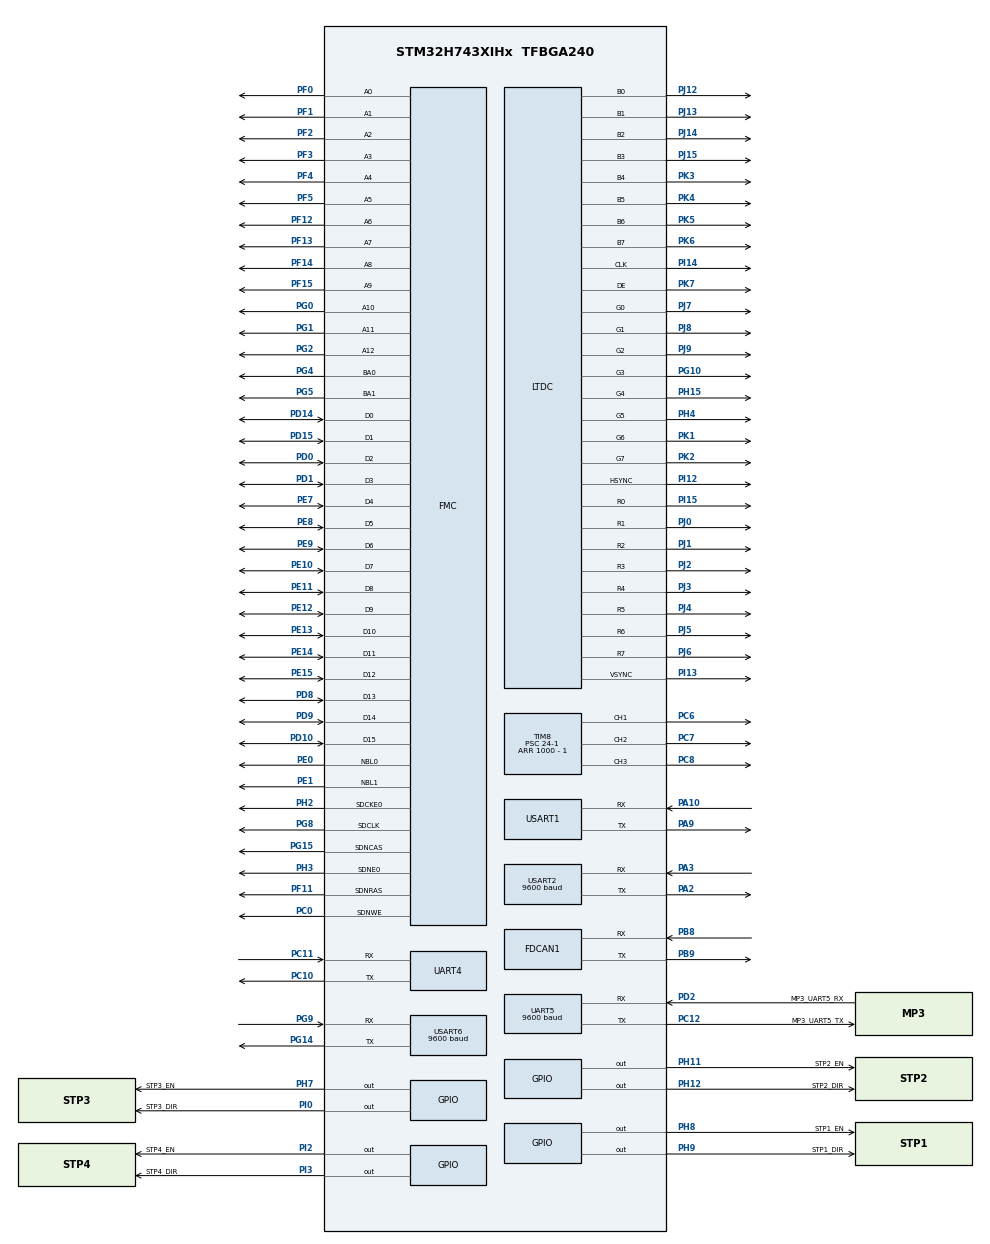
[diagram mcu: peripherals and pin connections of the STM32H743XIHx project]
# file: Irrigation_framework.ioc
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CORTEX_M7.AccessPermission_S-Cortex_Memory_Protection_Unit_Region1_Settings_S=MPU_REGION_FULL_ACCESS
CORTEX_M7.AccessPermission_Spec=MPU_REGION_FULL_ACCESS
CORTEX_M7.BaseAddress_S-Cortex_Memory_Protection_Unit_Region1_Settings_S=0xC0000000
CORTEX_M7.BaseAddress_Spec=0x24000000
CORTEX_M7.CPU_DCache=Enabled
CORTEX_M7.CPU_ICache=Enabled
CORTEX_M7.DisableExec_Spec=MPU_INSTRUCTION_ACCESS_ENABLE
CORTEX_M7.Enable_S-Cortex_Memory_Protection_Unit_Region1_Settings_S=MPU_REGION_ENABLE
CORTEX_M7.Enable_S-Cortex_Memory_Protection_Unit_Region2_Settings_S=__NULL
CORTEX_M7.Enable_S-Cortex_Memory_Protection_Unit_Region3_Settings_S=__NULL
CORTEX_M7.Enable_S-Cortex_Memory_Protection_Unit_Region4_Settings_S=__NULL
CORTEX_M7.Enable_S-Cortex_Memory_Protection_Unit_Region5_Settings_S=__NULL
CORTEX_M7.Enable_S-Cortex_Memory_Protection_Unit_Region6_Settings_S=__NULL
CORTEX_M7.Enable_Spec=MPU_REGION_ENABLE
CORTEX_M7.IsBufferable_S-Cortex_Memory_Protection_Unit_Region1_Settings_S=MPU_ACCESS_BUFFERABLE
CORTEX_M7.IsBufferable_Spec=MPU_ACCESS_NOT_BUFFERABLE
CORTEX_M7.IsCacheable_S-Cortex_Memory_Protection_Unit_Region1_Settings_S=MPU_ACCESS_CACHEABLE
CORTEX_M7.IsCacheable_Spec=MPU_ACCESS_NOT_CACHEABLE
CORTEX_M7.IsShareable_Spec=MPU_ACCESS_NOT_SHAREABLE
CORTEX_M7.MPU_Control=MPU_PRIVILEGED_DEFAULT
CORTEX_M7.Size_S-Cortex_Memory_Protection_Unit_Region1_Settings_S=MPU_REGION_SIZE_32MB
CORTEX_M7.Size_Spec=MPU_REGION_SIZE_2KB
CORTEX_M7.SubRegionDisable_Spec=0x0
CORTEX_M7.TypeExtField_Spec=MPU_TEX_LEVEL1
CORTEX_M7.default_mode_Activation=1
DMA2D.ColorMode=DMA2D_OUTPUT_RGB565
Dma.Request0=USART2_RX
Dma.Request1=USART1_RX
Dma.Request2=UART4_RX
Dma.UART4_RX.2.Direction=DMA_PERIPH_TO_MEMORY
Dma.UART4_RX.2.EventEnable=DISABLE
Dma.UART4_RX.2.FIFOMode=DMA_FIFOMODE_DISABLE
Dma.UART4_RX.2.Instance=DMA1_Stream3
Dma.UART4_RX.2.MemDataAlignment=DMA_MDATAALIGN_BYTE
Dma.UART4_RX.2.MemInc=DMA_MINC_ENABLE
Dma.UART4_RX.2.Mode=DMA_NORMAL
Dma.UART4_RX.2.PeriphDataAlignment=DMA_PDATAALIGN_BYTE
Dma.UART4_RX.2.PeriphInc=DMA_PINC_DISABLE
Dma.UART4_RX.2.Polarity=HAL_DMAMUX_REQ_GEN_RISING
Dma.UART4_RX.2.Priority=DMA_PRIORITY_HIGH
Dma.UART4_RX.2.RequestNumber=1
Dma.UART4_RX.2.SignalID=NONE
Dma.UART4_RX.2.SyncEnable=DISABLE
Dma.UART4_RX.2.SyncPolarity=HAL_DMAMUX_SYNC_NO_EVENT
Dma.UART4_RX.2.SyncRequestNumber=1
Dma.UART4_RX.2.SyncSignalID=NONE
Dma.USART1_RX.1.Direction=DMA_PERIPH_TO_MEMORY
Dma.USART1_RX.1.EventEnable=DISABLE
Dma.USART1_RX.1.FIFOMode=DMA_FIFOMODE_DISABLE
Dma.USART1_RX.1.Instance=DMA1_Stream1
Dma.USART1_RX.1.MemDataAlignment=DMA_MDATAALIGN_BYTE
Dma.USART1_RX.1.MemInc=DMA_MINC_ENABLE
Dma.USART1_RX.1.Mode=DMA_NORMAL
Dma.USART1_RX.1.PeriphDataAlignment=DMA_PDATAALIGN_BYTE
Dma.USART1_RX.1.PeriphInc=DMA_PINC_DISABLE
Dma.USART1_RX.1.Polarity=HAL_DMAMUX_REQ_GEN_RISING
Dma.USART1_RX.1.Priority=DMA_PRIORITY_HIGH
Dma.USART1_RX.1.RequestNumber=1
Dma.USART1_RX.1.SignalID=NONE
Dma.USART1_RX.1.SyncEnable=DISABLE
Dma.USART1_RX.1.SyncPolarity=HAL_DMAMUX_SYNC_NO_EVENT
Dma.USART1_RX.1.SyncRequestNumber=1
Dma.USART1_RX.1.SyncSignalID=NONE
Dma.USART2_RX.0.Direction=DMA_PERIPH_TO_MEMORY
Dma.USART2_RX.0.EventEnable=DISABLE
Dma.USART2_RX.0.FIFOMode=DMA_FIFOMODE_DISABLE
Dma.USART2_RX.0.Instance=DMA1_Stream0
Dma.USART2_RX.0.MemDataAlignment=DMA_MDATAALIGN_BYTE
Dma.USART2_RX.0.MemInc=DMA_MINC_ENABLE
Dma.USART2_RX.0.Mode=DMA_NORMAL
Dma.USART2_RX.0.PeriphDataAlignment=DMA_PDATAALIGN_BYTE
Dma.USART2_RX.0.PeriphInc=DMA_PINC_DISABLE
Dma.USART2_RX.0.Polarity=HAL_DMAMUX_REQ_GEN_RISING
Dma.USART2_RX.0.Priority=DMA_PRIORITY_VERY_HIGH
Dma.USART2_RX.0.RequestNumber=1
Dma.USART2_RX.0.SignalID=NONE
Dma.USART2_RX.0.SyncEnable=DISABLE
Dma.USART2_RX.0.SyncPolarity=HAL_DMAMUX_SYNC_NO_EVENT
Dma.USART2_RX.0.SyncRequestNumber=1
Dma.USART2_RX.0.SyncSignalID=NONE
FDCAN1.AutoRetransmission=ENABLE
FDCAN1.CalculateBaudRateNominal=1000000
FDCAN1.CalculateTimeBitNominal=1000
FDCAN1.CalculateTimeQuantumNominal=200.0
FDCAN1.DataPrescaler=12
FDCAN1.DataSyncJumpWidth=2
FDCAN1.DataTimeSeg1=7
FDCAN1.DataTimeSeg2=2
FDCAN1.NominalPrescaler=5
FDCAN1.NominalSyncJumpWidth=2
FDCAN1.NominalTimeSeg1=2
FDCAN1.NominalTimeSeg2=2
FDCAN1.ProtocolException=ENABLE
FDCAN1.RxFifo0ElmtsNbr=32
FDCAN1.StdFiltersNbr=1
FDCAN1.TxFifoQueueElmtsNbr=16
FMC.CASLatency1=FMC_SDRAM_CAS_LATENCY_3
FMC.ColumnBitsNumber1=FMC_SDRAM_COLUMN_BITS_NUM_9
FMC.ExitSelfRefreshDelay1=7
FMC.LoadToActiveDelay1=2
FMC.RCDDelay1=2
FMC.RPDelay1=2
FMC.RPDelay2=2
FMC.ReadBurst1=FMC_SDRAM_RBURST_ENABLE
FMC.ReadBurst2=FMC_SDRAM_RBURST_ENABLE
FMC.RowCycleDelay1=7
FMC.RowCycleDelay2=7
FMC.SDClockPeriod1=FMC_SDRAM_CLOCK_PERIOD_2
FMC.SDClockPeriod2=FMC_SDRAM_CLOCK_PERIOD_2
FMC.SelfRefreshTime1=4
FMC.WriteRecoveryTime1=3
FREERTOS.Tasks01=defaultTask,0,128,StartDefaultTask,Default,NULL,Dynamic,NULL,NULL
FREERTOS.configCHECK_FOR_STACK_OVERFLOW=2
FREERTOS.configENABLE_FPU=1
FREERTOS.configTOTAL_HEAP_SIZE=40960
FREERTOS.configUSE_TIMERS=1
LTDC.ActiveW=800
LTDC.Alpha_L0=255
LTDC.FBStartAdress_L0=0xC0000000
LTDC.HBP=80
LTDC.HFP=200
LTDC.HSync=1
LTDC.ImageHeight_L0=480
LTDC.ImageWidth_L0=800
LTDC.Layers=0
LTDC.PixelFormat_L0=LTDC_PIXEL_FORMAT_RGB565
LTDC.VBP=40
LTDC.VFP=22
LTDC.VSync=1
LTDC.WindowX1_L0=800
LTDC.WindowY1_L0=480
Mcu.Family=STM32H7
Mcu.Name=STM32H743XIHx
Mcu.Package=TFBGA240
NVIC.DMA1_Stream0_IRQn=true\:5\:0\:false\:false\:true\:true\:false\:true\:true
NVIC.DMA1_Stream1_IRQn=true\:5\:0\:false\:false\:true\:true\:false\:true\:true
NVIC.DMA1_Stream3_IRQn=true\:5\:0\:false\:false\:true\:true\:false\:true\:true
NVIC.FDCAN1_IT0_IRQn=true\:5\:0\:false\:false\:true\:true\:true\:true\:true
NVIC.FDCAN1_IT1_IRQn=true\:5\:0\:false\:false\:true\:true\:true\:true\:true
NVIC.PriorityGroup=NVIC_PRIORITYGROUP_4
NVIC.TIM1_UP_IRQn=true\:15\:0\:true\:false\:true\:false\:false\:true\:true
NVIC.TimeBase=TIM1_UP_IRQn
NVIC.TimeBaseIP=TIM1
NVIC.UART4_IRQn=true\:5\:0\:false\:false\:true\:true\:true\:true\:true
NVIC.UART5_IRQn=true\:5\:0\:true\:false\:true\:true\:true\:true\:true
NVIC.USART1_IRQn=true\:5\:0\:false\:false\:true\:true\:true\:true\:true
NVIC.USART2_IRQn=true\:5\:0\:false\:false\:true\:true\:true\:true\:true
NVIC.USART6_IRQn=true\:5\:0\:false\:false\:true\:true\:true\:true\:true
PA10.GPIO_Speed=GPIO_SPEED_FREQ_HIGH
PA10.Mode=Asynchronous
PA10.Signal=USART1_RX
PA13\ (JTMS/SWDIO).Mode=Serial_Wire
PA13\ (JTMS/SWDIO).Signal=DEBUG_JTMS-SWDIO
PA14\ (JTCK/SWCLK).Mode=Serial_Wire
PA14\ (JTCK/SWCLK).Signal=DEBUG_JTCK-SWCLK
PA2.GPIO_ModeDefaultPP=GPIO_MODE_AF_PP
PA2.GPIO_PuPd=GPIO_NOPULL
PA2.GPIO_Speed=GPIO_SPEED_FREQ_HIGH
PA2.Mode=Asynchronous
PA2.Signal=USART2_TX
PA3.GPIO_ModeDefaultPP=GPIO_MODE_AF_PP
PA3.GPIO_PuPd=GPIO_NOPULL
PA3.GPIO_Speed=GPIO_SPEED_FREQ_HIGH
PA3.Mode=Asynchronous
PA3.Signal=USART2_RX
PA9.GPIO_Speed=GPIO_SPEED_FREQ_HIGH
PA9.Mode=Asynchronous
PA9.Signal=USART1_TX
PB8.GPIO_Speed=GPIO_SPEED_FREQ_VERY_HIGH
PB8.Mode=FDCAN_Activate
PB8.Signal=FDCAN1_RX
PB9.GPIO_Speed=GPIO_SPEED_FREQ_VERY_HIGH
PB9.Mode=FDCAN_Activate
PB9.Signal=FDCAN1_TX
PC0.Signal=FMC_SDNWE
PC10.GPIO_ModeDefaultPP=GPIO_MODE_AF_PP
PC10.GPIO_PuPd=GPIO_NOPULL
PC10.GPIO_Speed=GPIO_SPEED_FREQ_HIGH
PC10.Mode=Asynchronous
PC10.Signal=UART4_TX
PC11.GPIO_ModeDefaultPP=GPIO_MODE_AF_PP
PC11.GPIO_PuPd=GPIO_NOPULL
PC11.GPIO_Speed=GPIO_SPEED_FREQ_HIGH
PC11.Mode=Asynchronous
PC11.Signal=UART4_RX
PC12.GPIO_Label=MP3_UART5_TX
PC12.GPIO_Speed=GPIO_SPEED_FREQ_HIGH
PC12.Mode=Asynchronous
PC12.Signal=UART5_TX
PC14-OSC32_IN\ (OSC32_IN).Mode=LSE-External-Oscillator
PC14-OSC32_IN\ (OSC32_IN).Signal=RCC_OSC32_IN
PC15-OSC32_OUT\ (OSC32_OUT).Mode=LSE-External-Oscillator
PC15-OSC32_OUT\ (OSC32_OUT).Signal=RCC_OSC32_OUT
PC6.GPIO_PuPd=GPIO_NOPULL
PC6.GPIO_Speed=GPIO_SPEED_FREQ_VERY_HIGH
PC6.Signal=S_TIM8_CH1
PC7.GPIO_Speed=GPIO_SPEED_FREQ_VERY_HIGH
PC7.Signal=S_TIM8_CH2
PC8.GPIO_Speed=GPIO_SPEED_FREQ_VERY_HIGH
PC8.Signal=S_TIM8_CH3
PD0.Signal=FMC_D2_DA2
PD1.Signal=FMC_D3_DA3
PD10.Signal=FMC_D15_DA15
PD14.Signal=FMC_D0_DA0
PD15.Signal=FMC_D1_DA1
PD2.GPIO_Label=MP3_UART5_RX
PD2.GPIO_Speed=GPIO_SPEED_FREQ_HIGH
PD2.Mode=Asynchronous
PD2.Signal=UART5_RX
PD8.PinAttribute=Free
PD8.Signal=FMC_D13_DA13
PD9.Signal=FMC_D14_DA14
PE0.Signal=FMC_NBL0
PE1.Signal=FMC_NBL1
PE10.Signal=FMC_D7_DA7
PE11.Signal=FMC_D8_DA8
PE12.Signal=FMC_D9_DA9
PE13.Signal=FMC_D10_DA10
PE14.PinAttribute=Free
PE14.Signal=FMC_D11_DA11
PE15.Signal=FMC_D12_DA12
PE7.PinAttribute=Free
PE7.Signal=FMC_D4_DA4
PE8.Signal=FMC_D5_DA5
PE9.Signal=FMC_D6_DA6
PF0.Signal=FMC_A0
PF1.Signal=FMC_A1
PF11.Signal=FMC_SDNRAS
PF12.Signal=FMC_A6
PF13.Signal=FMC_A7
PF14.Signal=FMC_A8
PF15.Signal=FMC_A9
PF2.Signal=FMC_A2
PF3.Signal=FMC_A3
PF4.Signal=FMC_A4
PF5.Signal=FMC_A5
PG0.Signal=FMC_A10
PG1.PinAttribute=Free
PG1.Signal=FMC_A11
PG10.GPIO_Speed=GPIO_SPEED_FREQ_VERY_HIGH
PG10.Mode=RGB888
PG10.Signal=LTDC_G3
PG14.GPIO_Speed=GPIO_SPEED_FREQ_HIGH
PG14.Mode=Asynchronous
PG14.Signal=USART6_TX
PG15.Signal=FMC_SDNCAS
PG2.Signal=FMC_A12
PG4.Signal=FMC_A14_BA0
PG5.Signal=FMC_A15_BA1
PG8.Signal=FMC_SDCLK
PG9.GPIO_Speed=GPIO_SPEED_FREQ_HIGH
PG9.Mode=Asynchronous
PG9.Signal=USART6_RX
PH0-OSC_IN\ (PH0).Mode=HSE-External-Oscillator
PH0-OSC_IN\ (PH0).Signal=RCC_OSC_IN
PH1-OSC_OUT\ (PH1).Mode=HSE-External-Oscillator
PH1-OSC_OUT\ (PH1).Signal=RCC_OSC_OUT
PH11.GPIO_Label=STP2_EN
PH11.GPIO_Speed=GPIO_SPEED_FREQ_MEDIUM
PH11.Signal=GPIO_Output
PH12.GPIO_Label=STP2_DIR
PH12.GPIO_Speed=GPIO_SPEED_FREQ_MEDIUM
PH12.Signal=GPIO_Output
PH15.GPIO_Speed=GPIO_SPEED_FREQ_VERY_HIGH
PH15.Mode=RGB888
PH15.Signal=LTDC_G4
PH2.Mode=SdramChipSelect1_1
PH2.Signal=FMC_SDCKE0
PH3.Mode=SdramChipSelect1_1
PH3.Signal=FMC_SDNE0
PH4.GPIO_Speed=GPIO_SPEED_FREQ_VERY_HIGH
PH4.Mode=RGB888
PH4.Signal=LTDC_G5
PH7.GPIO_Label=STP3_EN
PH7.GPIO_Speed=GPIO_SPEED_FREQ_MEDIUM
PH7.PinState=GPIO_PIN_RESET
PH7.Signal=GPIO_Output
PH8.GPIO_Label=STP1_EN
PH8.GPIO_ModeDefaultOutputPP=GPIO_MODE_OUTPUT_PP
PH8.GPIO_PuPd=GPIO_NOPULL
PH8.GPIO_Speed=GPIO_SPEED_FREQ_MEDIUM
PH8.PinState=GPIO_PIN_RESET
PH8.Signal=GPIO_Output
PH9.GPIO_Label=STP1_DIR
PH9.GPIO_Speed=GPIO_SPEED_FREQ_MEDIUM
PH9.Signal=GPIO_Output
PI0.GPIO_Label=STP3_DIR
PI0.GPIO_Speed=GPIO_SPEED_FREQ_MEDIUM
PI0.Signal=GPIO_Output
PI12.GPIO_Speed=GPIO_SPEED_FREQ_VERY_HIGH
PI12.Mode=RGB888
PI12.Signal=LTDC_HSYNC
PI13.GPIO_Speed=GPIO_SPEED_FREQ_VERY_HIGH
PI13.Mode=RGB888
PI13.Signal=LTDC_VSYNC
PI14.GPIO_Speed=GPIO_SPEED_FREQ_VERY_HIGH
PI14.Mode=RGB888
PI14.Signal=LTDC_CLK
PI15.GPIO_Speed=GPIO_SPEED_FREQ_VERY_HIGH
PI15.Mode=RGB888
PI15.Signal=LTDC_R0
PI2.GPIO_Label=STP4_EN
PI2.GPIO_Speed=GPIO_SPEED_FREQ_MEDIUM
PI2.Signal=GPIO_Output
PI3.GPIO_Label=STP4_DIR
PI3.GPIO_Speed=GPIO_SPEED_FREQ_MEDIUM
PI3.Signal=GPIO_Output
PJ0.GPIO_Speed=GPIO_SPEED_FREQ_VERY_HIGH
PJ0.Mode=RGB888
PJ0.Signal=LTDC_R1
PJ1.GPIO_Speed=GPIO_SPEED_FREQ_VERY_HIGH
PJ1.Mode=RGB888
PJ1.Signal=LTDC_R2
PJ12.GPIO_Speed=GPIO_SPEED_FREQ_VERY_HIGH
PJ12.Mode=RGB888
PJ12.Signal=LTDC_B0
PJ13.GPIO_Speed=GPIO_SPEED_FREQ_VERY_HIGH
PJ13.Mode=RGB888
PJ13.Signal=LTDC_B1
PJ14.GPIO_Speed=GPIO_SPEED_FREQ_VERY_HIGH
PJ14.Mode=RGB888
PJ14.Signal=LTDC_B2
PJ15.GPIO_Speed=GPIO_SPEED_FREQ_VERY_HIGH
PJ15.Mode=RGB888
PJ15.Signal=LTDC_B3
PJ2.GPIO_Speed=GPIO_SPEED_FREQ_VERY_HIGH
PJ2.Mode=RGB888
PJ2.Signal=LTDC_R3
PJ3.GPIO_Speed=GPIO_SPEED_FREQ_VERY_HIGH
PJ3.Mode=RGB888
PJ3.Signal=LTDC_R4
PJ4.GPIO_Speed=GPIO_SPEED_FREQ_VERY_HIGH
PJ4.Mode=RGB888
PJ4.Signal=LTDC_R5
PJ5.GPIO_Speed=GPIO_SPEED_FREQ_VERY_HIGH
PJ5.Mode=RGB888
PJ5.Signal=LTDC_R6
PJ6.GPIO_Speed=GPIO_SPEED_FREQ_VERY_HIGH
PJ6.Mode=RGB888
PJ6.Signal=LTDC_R7
PJ7.GPIO_Speed=GPIO_SPEED_FREQ_VERY_HIGH
PJ7.Mode=RGB888
PJ7.Signal=LTDC_G0
PJ8.GPIO_Speed=GPIO_SPEED_FREQ_VERY_HIGH
PJ8.Mode=RGB888
PJ8.Signal=LTDC_G1
PJ9.GPIO_Speed=GPIO_SPEED_FREQ_VERY_HIGH
PJ9.Mode=RGB888
PJ9.Signal=LTDC_G2
PK1.GPIO_Speed=GPIO_SPEED_FREQ_VERY_HIGH
PK1.Mode=RGB888
PK1.Signal=LTDC_G6
PK2.GPIO_Speed=GPIO_SPEED_FREQ_VERY_HIGH
PK2.Mode=RGB888
PK2.Signal=LTDC_G7
PK3.GPIO_Speed=GPIO_SPEED_FREQ_VERY_HIGH
PK3.Mode=RGB888
PK3.Signal=LTDC_B4
PK4.GPIO_Speed=GPIO_SPEED_FREQ_VERY_HIGH
PK4.Mode=RGB888
PK4.Signal=LTDC_B5
PK5.GPIO_Speed=GPIO_SPEED_FREQ_VERY_HIGH
PK5.Mode=RGB888
PK5.Signal=LTDC_B6
PK6.GPIO_Speed=GPIO_SPEED_FREQ_VERY_HIGH
PK6.Mode=RGB888
PK6.Signal=LTDC_B7
PK7.GPIO_Speed=GPIO_SPEED_FREQ_VERY_HIGH
PK7.Mode=RGB888
PK7.Signal=LTDC_DE
ProjectManager.HeapSize=0x2000
ProjectManager.StackSize=0x4000
ProjectManager.TargetToolchain=Makefile
RCC.ADCFreq_Value=50390625
RCC.APB1Freq_Value=120000000
RCC.APB2Freq_Value=120000000
RCC.APB3Freq_Value=120000000
RCC.APB4Freq_Value=120000000
RCC.CortexFreq_Value=480000000
RCC.D1PPRE=RCC_APB3_DIV2
RCC.D2PPRE1=RCC_APB1_DIV2
RCC.D2PPRE2=RCC_APB2_DIV2
RCC.D3PPRE=RCC_APB4_DIV2
RCC.DIVM1=5
RCC.DIVM3=25
RCC.DIVN1=192
RCC.DIVN3=330
RCC.DIVR3=10
RCC.FDCANCLockSelection=RCC_FDCANCLKSOURCE_HSE
RCC.HCLKFreq_Value=240000000
RCC.HPRE=RCC_HCLK_DIV2
RCC.PLL2FRACN=0
RCC.PLL3FRACN=0
RCC.PLLFRACN=0
RCC.PLLSourceVirtual=RCC_PLLSOURCE_HSE
RCC.SYSCLKFreq_VALUE=480000000
RCC.SYSCLKSource=RCC_SYSCLKSOURCE_PLLCLK
RCC.USBFreq_Value=480000000
SH.FMC_A0.0=FMC_A0,13b-sda1
SH.FMC_A1.0=FMC_A1,13b-sda1
SH.FMC_A10.0=FMC_A10,13b-sda1
SH.FMC_A11.0=FMC_A11,13b-sda1
SH.FMC_A12.0=FMC_A12,13b-sda1
SH.FMC_A14_BA0.0=FMC_BA0,FourSdramBanks1
SH.FMC_A15_BA1.0=FMC_BA1,FourSdramBanks1
SH.FMC_A2.0=FMC_A2,13b-sda1
SH.FMC_A3.0=FMC_A3,13b-sda1
SH.FMC_A4.0=FMC_A4,13b-sda1
SH.FMC_A5.0=FMC_A5,13b-sda1
SH.FMC_A6.0=FMC_A6,13b-sda1
SH.FMC_A7.0=FMC_A7,13b-sda1
SH.FMC_A8.0=FMC_A8,13b-sda1
SH.FMC_A9.0=FMC_A9,13b-sda1
SH.FMC_D0_DA0.0=FMC_D0,sd-16b-d1
SH.FMC_D10_DA10.0=FMC_D10,sd-16b-d1
SH.FMC_D11_DA11.0=FMC_D11,sd-16b-d1
SH.FMC_D12_DA12.0=FMC_D12,sd-16b-d1
SH.FMC_D13_DA13.0=FMC_D13,sd-16b-d1
SH.FMC_D14_DA14.0=FMC_D14,sd-16b-d1
SH.FMC_D15_DA15.0=FMC_D15,sd-16b-d1
SH.FMC_D1_DA1.0=FMC_D1,sd-16b-d1
SH.FMC_D2_DA2.0=FMC_D2,sd-16b-d1
SH.FMC_D3_DA3.0=FMC_D3,sd-16b-d1
SH.FMC_D4_DA4.0=FMC_D4,sd-16b-d1
SH.FMC_D5_DA5.0=FMC_D5,sd-16b-d1
SH.FMC_D6_DA6.0=FMC_D6,sd-16b-d1
SH.FMC_D7_DA7.0=FMC_D7,sd-16b-d1
SH.FMC_D8_DA8.0=FMC_D8,sd-16b-d1
SH.FMC_D9_DA9.0=FMC_D9,sd-16b-d1
SH.FMC_NBL0.0=FMC_NBL0,Sd2ByteEnable1
SH.FMC_NBL1.0=FMC_NBL1,Sd2ByteEnable1
SH.FMC_SDCLK.0=FMC_SDCLK,13b-sda1
SH.FMC_SDNCAS.0=FMC_SDNCAS,13b-sda1
SH.FMC_SDNRAS.0=FMC_SDNRAS,13b-sda1
SH.FMC_SDNWE.0=FMC_SDNWE,13b-sda1
SH.S_TIM8_CH1.0=TIM8_CH1,PWM Generation1 CH1
SH.S_TIM8_CH2.0=TIM8_CH2,PWM Generation2 CH2
SH.S_TIM8_CH3.0=TIM8_CH3,PWM Generation3 CH3
STMicroelectronics.X-CUBE-ALGOBUILD.1.4.0.LibraryCcDSPOoLibraryJjDSPOoLibrary=true
TIM8.Channel-PWM\ Generation1\ CH1=TIM_CHANNEL_1
TIM8.Channel-PWM\ Generation2\ CH2=TIM_CHANNEL_2
TIM8.Channel-PWM\ Generation3\ CH3=TIM_CHANNEL_3
TIM8.OCFastMode_PWM-PWM\ Generation1\ CH1=TIM_OCFAST_ENABLE
TIM8.OCFastMode_PWM-PWM\ Generation2\ CH2=TIM_OCFAST_ENABLE
TIM8.OCFastMode_PWM-PWM\ Generation3\ CH3=TIM_OCFAST_ENABLE
TIM8.OCPolarity_1=TIM_OCPOLARITY_LOW
TIM8.OCPolarity_2=TIM_OCPOLARITY_LOW
TIM8.OCPolarity_3=TIM_OCPOLARITY_LOW
TIM8.Period=1000 - 1
TIM8.Prescaler=24-1
TIM8.Pulse-PWM\ Generation1\ CH1=500-1
TIM8.Pulse-PWM\ Generation2\ CH2=500-1
TIM8.Pulse-PWM\ Generation3\ CH3=500-1
TIM8.TIM_MasterOutputTrigger=TIM_TRGO_UPDATE
TIM8.TIM_MasterSlaveMode=TIM_MASTERSLAVEMODE_ENABLE
UART5.BaudRate=9600
UART5.Mode=MODE_TX
USART1.FIFOMode=FIFOMODE_ENABLE
USART1.VirtualMode-Asynchronous=VM_ASYNC
USART2.BaudRate=9600
USART2.VirtualMode-Asynchronous=VM_ASYNC
USART6.BaudRate=9600
USART6.VirtualMode-Asynchronous=VM_ASYNC
VP_CRC_VS_CRC.Mode=CRC_Activate
VP_DMA2D_VS_DMA2D.Mode=DMA2D_Activate
VP_FREERTOS_VS_CMSIS_V1.Mode=CMSIS_V1
VP_MEMORYMAP_VS_MEMORYMAP.Mode=CurAppReg
VP_RNG_VS_RNG.Mode=RNG_Activate
VP_RTC_VS_RTC_Activate.Mode=RTC_Enabled
VP_STMicroelectronics.X-CUBE-ALGOBUILD_VS_DSPOoLibraryJjLibrary_1.4.0_1.4.0.Mode=DSPOoLibraryJjLibrary
VP_SYS_VS_tim1.Mode=TIM1
VP_TIM2_VS_ClockSourceITR.Mode=TriggerSource_ITR1
VP_TIM2_VS_ControllerModeClock.Mode=Clock Mode
VP_TIM4_VS_ClockSourceITR.Mode=TriggerSource_ITR3
VP_TIM4_VS_ControllerModeClock.Mode=Clock Mode
VP_TIM5_VS_ClockSourceITR.Mode=TriggerSource_ITR1
VP_TIM5_VS_ControllerModeClock.Mode=Clock Mode
VP_TIM8_VS_ClockSourceINT.Mode=Internal
board=custom

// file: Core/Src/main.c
/* USER CODE BEGIN Header */
/**
 ******************************************************************************
 * @file           : main.c
 * @brief          : Main program body
 ******************************************************************************
 * @attention
 *
 * Copyright (c) 2024 STMicroelectronics.
 * All rights reserved.
 *
 * This software is licensed under terms that can be found in the LICENSE file
 * in the root directory of this software component.
 * If no LICENSE file comes with this software, it is provided AS-IS.
 *
 ******************************************************************************
 */
/* USER CODE END Header */
#include "main.h"
#include "cmsis_os.h"
#include "crc.h"
#include "dma.h"
#include "dma2d.h"
#include "fdcan.h"
#include "ltdc.h"
#include "memorymap.h"
#include "rng.h"
#include "rtc.h"
#include "tim.h"
#include "usart.h"
#include "gpio.h"
#include "fmc.h"

/* USER CODE BEGIN Includes */
#include "bsp_usart.h"
#include "robot.h"
#include "sdram.h"
#include "lcd_rgb.h"
#include "lcd_test.h"
/* USER CODE END Includes */

void SystemClock_Config(void);
static void MPU_Config(void);
void MX_FREERTOS_Init(void);

int main(void)
{

  /* MPU Configuration--------------------------------------------------------*/
  MPU_Config();

  /* Enable the CPU Cache */

  /* Enable I-Cache---------------------------------------------------------*/
  SCB_EnableICache();

  /* Enable D-Cache---------------------------------------------------------*/
  SCB_EnableDCache();

  /* MCU Configuration--------------------------------------------------------*/

  /* Reset of all peripherals, Initializes the Flash interface and the Systick. */
  HAL_Init();

  /* Configure the system clock */
  SystemClock_Config();

  /* Initialize all configured peripherals */
  MX_GPIO_Init();
  MX_DMA_Init();
  MX_UART5_Init();
  MX_CRC_Init();
  MX_FDCAN1_Init();
  MX_RNG_Init();
  MX_RTC_Init();
  MX_FMC_Init();
  MX_LTDC_Init();
  MX_DMA2D_Init();
  MX_USART2_UART_Init();
  MX_USART6_UART_Init();
  MX_TIM2_Init();
  MX_TIM4_Init();
  MX_TIM5_Init();
  MX_TIM8_Init();
  MX_USART1_UART_Init();
  MX_UART4_Init();
  /* USER CODE BEGIN 2 */
  /*------------------------LTDC Init-------------------------------
   */
  SDRAM_Initialization_Sequence(&hsdram1);
  LCD_RGB_Init();
  RobotInit();
  init_my_section();

  /*       for testing       */

  /* USER CODE END 2 */

  /* Call init function for freertos objects (in cmsis_os2.c) */
  MX_FREERTOS_Init();

  /* Start scheduler */
  osKernelStart();

  /* We should never get here as control is now taken by the scheduler */

  /* Infinite loop */
  while (1)
  {

  }
}

void SystemClock_Config(void)
{
  RCC_OscInitTypeDef RCC_OscInitStruct = {0};
  RCC_ClkInitTypeDef RCC_ClkInitStruct = {0};

  /** Supply configuration update enable
  */
  HAL_PWREx_ConfigSupply(PWR_LDO_SUPPLY);

  /** Configure the main internal regulator output voltage
  */
  __HAL_PWR_VOLTAGESCALING_CONFIG(PWR_REGULATOR_VOLTAGE_SCALE1);

  while(!__HAL_PWR_GET_FLAG(PWR_FLAG_VOSRDY)) {}

  __HAL_RCC_SYSCFG_CLK_ENABLE();
  __HAL_PWR_VOLTAGESCALING_CONFIG(PWR_REGULATOR_VOLTAGE_SCALE0);

  while(!__HAL_PWR_GET_FLAG(PWR_FLAG_VOSRDY)) {}

  /** Initializes the RCC Oscillators according to the specified parameters
  * in the RCC_OscInitTypeDef structure.
  */
  RCC_OscInitStruct.OscillatorType = RCC_OSCILLATORTYPE_HSI48|RCC_OSCILLATORTYPE_LSI
                              |RCC_OSCILLATORTYPE_HSE;
  RCC_OscInitStruct.HSEState = RCC_HSE_ON;
  RCC_OscInitStruct.LSIState = RCC_LSI_ON;
  RCC_OscInitStruct.HSI48State = RCC_HSI48_ON;
  RCC_OscInitStruct.PLL.PLLState = RCC_PLL_ON;
  RCC_OscInitStruct.PLL.PLLSource = RCC_PLLSOURCE_HSE;
  RCC_OscInitStruct.PLL.PLLM = 5;
  RCC_OscInitStruct.PLL.PLLN = 192;
  RCC_OscInitStruct.PLL.PLLP = 2;
  RCC_OscInitStruct.PLL.PLLQ = 2;
  RCC_OscInitStruct.PLL.PLLR = 2;
  RCC_OscInitStruct.PLL.PLLRGE = RCC_PLL1VCIRANGE_2;
  RCC_OscInitStruct.PLL.PLLVCOSEL = RCC_PLL1VCOWIDE;
  RCC_OscInitStruct.PLL.PLLFRACN = 0;
  if (HAL_RCC_OscConfig(&RCC_OscInitStruct) != HAL_OK)
  {
    Error_Handler();
  }

  /** Initializes the CPU, AHB and APB buses clocks
  */
  RCC_ClkInitStruct.ClockType = RCC_CLOCKTYPE_HCLK|RCC_CLOCKTYPE_SYSCLK
                              |RCC_CLOCKTYPE_PCLK1|RCC_CLOCKTYPE_PCLK2
                              |RCC_CLOCKTYPE_D3PCLK1|RCC_CLOCKTYPE_D1PCLK1;
  RCC_ClkInitStruct.SYSCLKSource = RCC_SYSCLKSOURCE_PLLCLK;
  RCC_ClkInitStruct.SYSCLKDivider = RCC_SYSCLK_DIV1;
  RCC_ClkInitStruct.AHBCLKDivider = RCC_HCLK_DIV2;
  RCC_ClkInitStruct.APB3CLKDivider = RCC_APB3_DIV2;
  RCC_ClkInitStruct.APB1CLKDivider = RCC_APB1_DIV2;
  RCC_ClkInitStruct.APB2CLKDivider = RCC_APB2_DIV2;
  RCC_ClkInitStruct.APB4CLKDivider = RCC_APB4_DIV2;

  if (HAL_RCC_ClockConfig(&RCC_ClkInitStruct, FLASH_LATENCY_4) != HAL_OK)
  {
    Error_Handler();
  }
}

 /* MPU Configuration */

void MPU_Config(void)
{
  MPU_Region_InitTypeDef MPU_InitStruct = {0};

  /* Disables the MPU */
  HAL_MPU_Disable();

  /** Initializes and configures the Region and the memory to be protected
  */
  MPU_InitStruct.Enable = MPU_REGION_ENABLE;
  MPU_InitStruct.Number = MPU_REGION_NUMBER0;
  MPU_InitStruct.BaseAddress = 0x24000000;
  MPU_InitStruct.Size = MPU_REGION_SIZE_2KB;
  MPU_InitStruct.SubRegionDisable = 0x0;
  MPU_InitStruct.TypeExtField = MPU_TEX_LEVEL1;
  MPU_InitStruct.AccessPermission = MPU_REGION_FULL_ACCESS;
  MPU_InitStruct.DisableExec = MPU_INSTRUCTION_ACCESS_ENABLE;
  MPU_InitStruct.IsShareable = MPU_ACCESS_NOT_SHAREABLE;
  MPU_InitStruct.IsCacheable = MPU_ACCESS_NOT_CACHEABLE;
  MPU_InitStruct.IsBufferable = MPU_ACCESS_NOT_BUFFERABLE;

  HAL_MPU_ConfigRegion(&MPU_InitStruct);

  /** Initializes and configures the Region and the memory to be protected
  */
  MPU_InitStruct.Number = MPU_REGION_NUMBER1;
  MPU_InitStruct.BaseAddress = 0xC0000000;
  MPU_InitStruct.Size = MPU_REGION_SIZE_32MB;
  MPU_InitStruct.TypeExtField = MPU_TEX_LEVEL0;
  MPU_InitStruct.IsCacheable = MPU_ACCESS_CACHEABLE;
  MPU_InitStruct.IsBufferable = MPU_ACCESS_BUFFERABLE;

  HAL_MPU_ConfigRegion(&MPU_InitStruct);
  /* Enables the MPU */
  HAL_MPU_Enable(MPU_PRIVILEGED_DEFAULT);

}

void HAL_TIM_PeriodElapsedCallback(TIM_HandleTypeDef *htim)
{
  if (htim->Instance == TIM1) {
    HAL_IncTick();
  }
}

void Error_Handler(void)
{
  __disable_irq();
  while (1)
  {
  }
}
